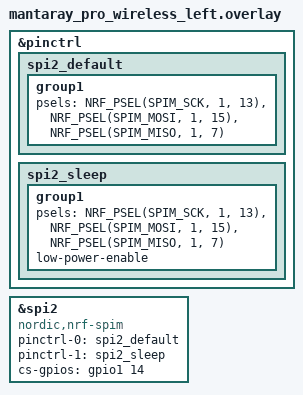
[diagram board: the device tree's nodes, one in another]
/*
 * Copyright (c) 2025 Colton Hawkins
 *
 * SPDX-License-Identifier: MIT
 */

#include "mantaray_pro_wireless.dtsi"

&pinctrl {
    spi2_default: spi2_default {
        group1 {
            psels = <NRF_PSEL(SPIM_SCK, 1, 13)>,
                    <NRF_PSEL(SPIM_MOSI, 1, 15)>,
                    <NRF_PSEL(SPIM_MISO, 1, 7)>;
        };
    };
    spi2_sleep: spi2_sleep {
        group1 {
            psels = <NRF_PSEL(SPIM_SCK, 1, 13)>,
                    <NRF_PSEL(SPIM_MOSI, 1, 15)>,
                    <NRF_PSEL(SPIM_MISO, 1, 7)>;
            low-power-enable;
        };
    };
};

nice_view_spi: &spi2 {
    compatible = "nordic,nrf-spim";
    pinctrl-0 = <&spi2_default>;
    pinctrl-1 = <&spi2_sleep>;
    pinctrl-names = "default", "sleep";
    cs-gpios = <&gpio1 14 GPIO_ACTIVE_HIGH>;
};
